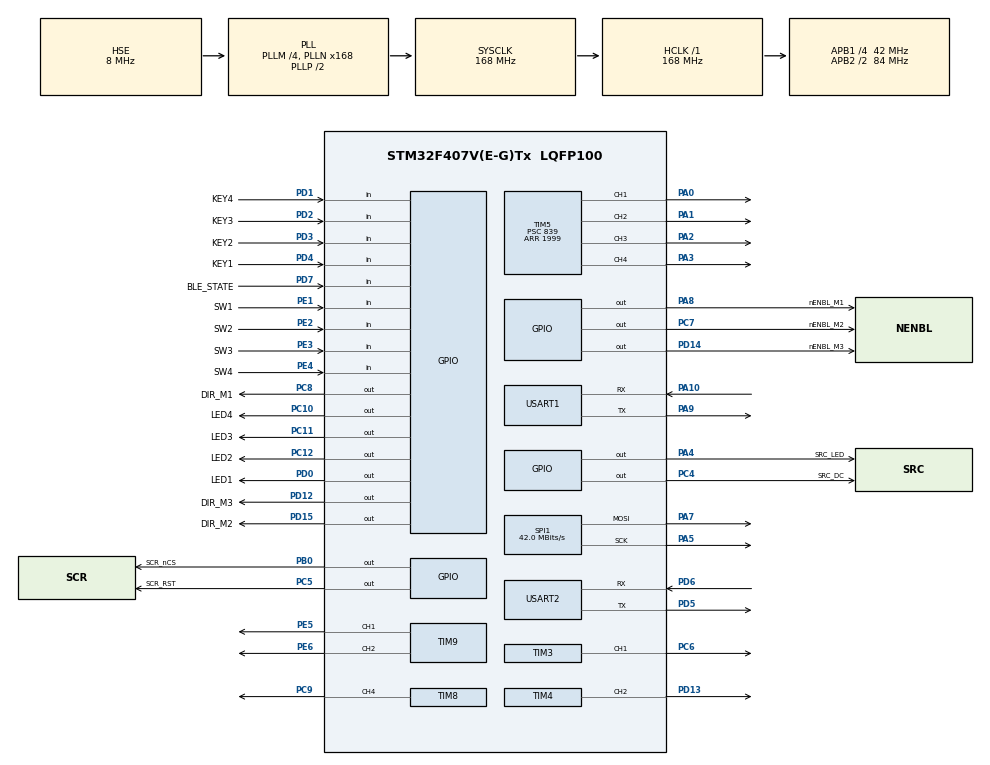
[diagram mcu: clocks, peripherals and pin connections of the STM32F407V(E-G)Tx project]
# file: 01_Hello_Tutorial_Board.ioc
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Dma.Request0=USART1_TX
Dma.Request1=USART1_RX
Dma.USART1_RX.1.Direction=DMA_PERIPH_TO_MEMORY
Dma.USART1_RX.1.FIFOMode=DMA_FIFOMODE_DISABLE
Dma.USART1_RX.1.Instance=DMA2_Stream2
Dma.USART1_RX.1.MemDataAlignment=DMA_MDATAALIGN_BYTE
Dma.USART1_RX.1.MemInc=DMA_MINC_ENABLE
Dma.USART1_RX.1.Mode=DMA_NORMAL
Dma.USART1_RX.1.PeriphDataAlignment=DMA_PDATAALIGN_BYTE
Dma.USART1_RX.1.PeriphInc=DMA_PINC_DISABLE
Dma.USART1_RX.1.Priority=DMA_PRIORITY_MEDIUM
Dma.USART1_TX.0.Direction=DMA_MEMORY_TO_PERIPH
Dma.USART1_TX.0.FIFOMode=DMA_FIFOMODE_DISABLE
Dma.USART1_TX.0.Instance=DMA2_Stream7
Dma.USART1_TX.0.MemDataAlignment=DMA_MDATAALIGN_BYTE
Dma.USART1_TX.0.MemInc=DMA_MINC_ENABLE
Dma.USART1_TX.0.Mode=DMA_NORMAL
Dma.USART1_TX.0.PeriphDataAlignment=DMA_PDATAALIGN_BYTE
Dma.USART1_TX.0.PeriphInc=DMA_PINC_DISABLE
Dma.USART1_TX.0.Priority=DMA_PRIORITY_MEDIUM
Mcu.Family=STM32F4
Mcu.Name=STM32F407V(E-G)Tx
Mcu.Package=LQFP100
NVIC.DMA2_Stream2_IRQn=true\:0\:0\:false\:false\:true\:false\:true\:true
NVIC.DMA2_Stream7_IRQn=true\:0\:0\:false\:false\:true\:false\:true\:true
NVIC.PriorityGroup=NVIC_PRIORITYGROUP_4
NVIC.TIM3_IRQn=true\:0\:0\:false\:false\:true\:true\:true\:true
NVIC.TIM4_IRQn=true\:0\:0\:false\:false\:true\:true\:true\:true
NVIC.TIM8_BRK_TIM12_IRQn=true\:0\:0\:false\:false\:true\:false\:true\:true
NVIC.TIM8_UP_TIM13_IRQn=true\:0\:0\:false\:false\:true\:false\:true\:true
NVIC.USART1_IRQn=true\:0\:0\:false\:false\:true\:true\:true\:true
PA0-WKUP.Signal=S_TIM5_CH1
PA1.Signal=S_TIM5_CH2
PA10.Mode=Asynchronous
PA10.Signal=USART1_RX
PA13.Mode=Trace_Asynchronous_SW
PA13.Signal=SYS_JTMS-SWDIO
PA14.Mode=Trace_Asynchronous_SW
PA14.Signal=SYS_JTCK-SWCLK
PA2.Signal=S_TIM5_CH3
PA3.Signal=S_TIM5_CH4
PA4.GPIO_Label=SRC_LED
PA4.Signal=GPIO_Output
PA5.Mode=TX_Only_Simplex_Unidirect_Master
PA5.Signal=SPI1_SCK
PA7.Mode=TX_Only_Simplex_Unidirect_Master
PA7.Signal=SPI1_MOSI
PA8.GPIO_Label=nENBL_M1
PA8.Signal=GPIO_Output
PA9.Mode=Asynchronous
PA9.Signal=USART1_TX
PB0.GPIO_Label=SCR_nCS
PB0.GPIO_Speed=GPIO_SPEED_FREQ_VERY_HIGH
PB0.PinState=GPIO_PIN_SET
PB0.Signal=GPIO_Output
PB3.Mode=Trace_Asynchronous_SW
PB3.Signal=SYS_JTDO-SWO
PC10.GPIO_Label=LED4
PC10.PinState=GPIO_PIN_SET
PC10.Signal=GPIO_Output
PC11.GPIO_Label=LED3
PC11.PinState=GPIO_PIN_SET
PC11.Signal=GPIO_Output
PC12.GPIO_Label=LED2
PC12.PinState=GPIO_PIN_SET
PC12.Signal=GPIO_Output
PC4.GPIO_Label=SRC_DC
PC4.GPIO_Speed=GPIO_SPEED_FREQ_VERY_HIGH
PC4.PinState=GPIO_PIN_RESET
PC4.Signal=GPIO_Output
PC5.GPIO_Label=SCR_RST
PC5.Signal=GPIO_Output
PC6.Signal=S_TIM3_CH1
PC7.GPIO_Label=nENBL_M2
PC7.Signal=GPIO_Output
PC8.GPIO_Label=DIR_M1
PC8.GPIO_Speed=GPIO_SPEED_FREQ_VERY_HIGH
PC8.PinState=GPIO_PIN_SET
PC8.Signal=GPIO_Output
PC9.Signal=S_TIM8_CH4
PD0.GPIO_Label=LED1
PD0.PinState=GPIO_PIN_SET
PD0.Signal=GPIO_Output
PD1.GPIO_Label=KEY4
PD1.Signal=GPIO_Input
PD12.GPIO_Label=DIR_M3
PD12.GPIO_Speed=GPIO_SPEED_FREQ_VERY_HIGH
PD12.PinState=GPIO_PIN_SET
PD12.Signal=GPIO_Output
PD13.Signal=S_TIM4_CH2
PD14.GPIO_Label=nENBL_M3
PD14.Signal=GPIO_Output
PD15.GPIO_Label=DIR_M2
PD15.GPIO_Speed=GPIO_SPEED_FREQ_VERY_HIGH
PD15.PinState=GPIO_PIN_SET
PD15.Signal=GPIO_Output
PD2.GPIO_Label=KEY3
PD2.Signal=GPIO_Input
PD3.GPIO_Label=KEY2
PD3.Signal=GPIO_Input
PD4.GPIO_Label=KEY1
PD4.Signal=GPIO_Input
PD5.Mode=Asynchronous
PD5.Signal=USART2_TX
PD6.Mode=Asynchronous
PD6.Signal=USART2_RX
PD7.GPIO_Label=BLE_STATE
PD7.Signal=GPIO_Input
PE1.GPIO_Label=SW1
PE1.Signal=GPIO_Input
PE2.GPIO_Label=SW2
PE2.Signal=GPIO_Input
PE3.GPIO_Label=SW3
PE3.Signal=GPIO_Input
PE4.GPIO_Label=SW4
PE4.Signal=GPIO_Input
PE5.Signal=S_TIM9_CH1
PE6.Signal=S_TIM9_CH2
PH0-OSC_IN.Mode=HSE-External-Oscillator
PH0-OSC_IN.Signal=RCC_OSC_IN
PH1-OSC_OUT.Mode=HSE-External-Oscillator
PH1-OSC_OUT.Signal=RCC_OSC_OUT
ProjectManager.HeapSize=0x800
ProjectManager.StackSize=0x800
ProjectManager.TargetToolchain=MDK-ARM V5.32
RCC.48MHZClocksFreq_Value=84000000
RCC.AHBFreq_Value=168000000
RCC.APB1CLKDivider=RCC_HCLK_DIV4
RCC.APB1Freq_Value=42000000
RCC.APB1TimFreq_Value=84000000
RCC.APB2CLKDivider=RCC_HCLK_DIV2
RCC.APB2Freq_Value=84000000
RCC.APB2TimFreq_Value=168000000
RCC.CortexFreq_Value=168000000
RCC.HCLKFreq_Value=168000000
RCC.HSE_VALUE=8000000
RCC.HSI_VALUE=16000000
RCC.LSE_VALUE=32768
RCC.PLLM=4
RCC.PLLN=168
RCC.PLLSourceVirtual=RCC_PLLSOURCE_HSE
RCC.SYSCLKFreq_VALUE=168000000
RCC.SYSCLKSource=RCC_SYSCLKSOURCE_PLLCLK
RCC.VCOOutputFreq_Value=336000000
SH.S_TIM3_CH1.0=TIM3_CH1,PWM Generation1 CH1
SH.S_TIM4_CH2.0=TIM4_CH2,PWM Generation2 CH2
SH.S_TIM5_CH1.0=TIM5_CH1,PWM Generation1 CH1
SH.S_TIM5_CH2.0=TIM5_CH2,PWM Generation2 CH2
SH.S_TIM5_CH3.0=TIM5_CH3,PWM Generation3 CH3
SH.S_TIM5_CH4.0=TIM5_CH4,PWM Generation4 CH4
SH.S_TIM8_CH4.0=TIM8_CH4,PWM Generation4 CH4
SH.S_TIM9_CH1.0=TIM9_CH1,PWM Generation1 CH1
SH.S_TIM9_CH2.0=TIM9_CH2,PWM Generation2 CH2
SPI1.BaudRatePrescaler=SPI_BAUDRATEPRESCALER_2
SPI1.CalculateBaudRate=42.0 MBits/s
SPI1.Direction=SPI_DIRECTION_2LINES
SPI1.Mode=SPI_MODE_MASTER
SPI1.VirtualType=VM_MASTER
TIM3.AutoReloadPreload=TIM_AUTORELOAD_PRELOAD_DISABLE
TIM3.Channel-PWM\ Generation1\ CH1=TIM_CHANNEL_1
TIM3.Period=999
TIM3.Prescaler=83
TIM3.Pulse-PWM\ Generation1\ CH1=500
TIM4.Channel-PWM\ Generation2\ CH2=TIM_CHANNEL_2
TIM4.Period=999
TIM4.Prescaler=83
TIM4.Pulse-PWM\ Generation2\ CH2=500
TIM5.AutoReloadPreload=TIM_AUTORELOAD_PRELOAD_DISABLE
TIM5.Channel-PWM\ Generation1\ CH1=TIM_CHANNEL_1
TIM5.Channel-PWM\ Generation2\ CH2=TIM_CHANNEL_2
TIM5.Channel-PWM\ Generation3\ CH3=TIM_CHANNEL_3
TIM5.Channel-PWM\ Generation4\ CH4=TIM_CHANNEL_4
TIM5.Period=1999
TIM5.Prescaler=839
TIM8.Channel-PWM\ Generation4\ CH4=TIM_CHANNEL_4
TIM8.Period=999
TIM8.Prescaler=83
TIM8.Pulse-PWM\ Generation4\ CH4=500
TIM9.Channel-PWM\ Generation1\ CH1=TIM_CHANNEL_1
TIM9.Channel-PWM\ Generation2\ CH2=TIM_CHANNEL_2
USART1.VirtualMode=VM_ASYNC
USART2.VirtualMode=VM_ASYNC
VP_TIM4_VS_ClockSourceINT.Mode=Internal
VP_TIM5_VS_ClockSourceINT.Mode=Internal
VP_TIM9_VS_ClockSourceINT.Mode=Internal
board=custom

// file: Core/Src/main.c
/* USER CODE BEGIN Header */
/**
  ******************************************************************************
  * @file           : main.c
  * @brief          : Main program body
  ******************************************************************************
  * @attention
  *
  * Copyright (c) 2023 STMicroelectronics.
  * All rights reserved.
  *
  * This software is licensed under terms that can be found in the LICENSE file
  * in the root directory of this software component.
  * If no LICENSE file comes with this software, it is provided AS-IS.
  *
  ******************************************************************************
  */
/* USER CODE END Header */
#include "main.h"
#include "dma.h"
#include "spi.h"
#include "tim.h"
#include "usart.h"
#include "gpio.h"

/* USER CODE BEGIN Includes */
#include "screen.h"
#include "image_repo.h"
/* USER CODE END Includes */

void SystemClock_Config(void);

int main(void)
{

  /* MCU Configuration--------------------------------------------------------*/

  /* Reset of all peripherals, Initializes the Flash interface and the Systick. */
  HAL_Init();

  /* Configure the system clock */
  SystemClock_Config();

  /* Initialize all configured peripherals */
  MX_GPIO_Init();
  MX_DMA_Init();
  MX_TIM3_Init();
  MX_TIM4_Init();
  MX_TIM5_Init();
  MX_TIM9_Init();
  MX_SPI1_Init();
  MX_USART1_UART_Init();
  MX_USART2_UART_Init();
  MX_TIM8_Init();
  /* USER CODE BEGIN 2 */

	Lcd_Init();
	LCDGUI_ShowImage(0, 0, 120, 120, BeiHangImageArray);

  /* USER CODE END 2 */

  /* Infinite loop */
  while (1)
  {

  }
}

void SystemClock_Config(void)
{
  RCC_OscInitTypeDef RCC_OscInitStruct = {0};
  RCC_ClkInitTypeDef RCC_ClkInitStruct = {0};

  /** Configure the main internal regulator output voltage
  */
  __HAL_RCC_PWR_CLK_ENABLE();
  __HAL_PWR_VOLTAGESCALING_CONFIG(PWR_REGULATOR_VOLTAGE_SCALE1);

  /** Initializes the RCC Oscillators according to the specified parameters
  * in the RCC_OscInitTypeDef structure.
  */
  RCC_OscInitStruct.OscillatorType = RCC_OSCILLATORTYPE_HSE;
  RCC_OscInitStruct.HSEState = RCC_HSE_ON;
  RCC_OscInitStruct.PLL.PLLState = RCC_PLL_ON;
  RCC_OscInitStruct.PLL.PLLSource = RCC_PLLSOURCE_HSE;
  RCC_OscInitStruct.PLL.PLLM = 4;
  RCC_OscInitStruct.PLL.PLLN = 168;
  RCC_OscInitStruct.PLL.PLLP = RCC_PLLP_DIV2;
  RCC_OscInitStruct.PLL.PLLQ = 4;
  if (HAL_RCC_OscConfig(&RCC_OscInitStruct) != HAL_OK)
  {
    Error_Handler();
  }

  /** Initializes the CPU, AHB and APB buses clocks
  */
  RCC_ClkInitStruct.ClockType = RCC_CLOCKTYPE_HCLK|RCC_CLOCKTYPE_SYSCLK
                              |RCC_CLOCKTYPE_PCLK1|RCC_CLOCKTYPE_PCLK2;
  RCC_ClkInitStruct.SYSCLKSource = RCC_SYSCLKSOURCE_PLLCLK;
  RCC_ClkInitStruct.AHBCLKDivider = RCC_SYSCLK_DIV1;
  RCC_ClkInitStruct.APB1CLKDivider = RCC_HCLK_DIV4;
  RCC_ClkInitStruct.APB2CLKDivider = RCC_HCLK_DIV2;

  if (HAL_RCC_ClockConfig(&RCC_ClkInitStruct, FLASH_LATENCY_5) != HAL_OK)
  {
    Error_Handler();
  }
}

void Error_Handler(void)
{
  __disable_irq();
  while (1)
  {
  }
}
